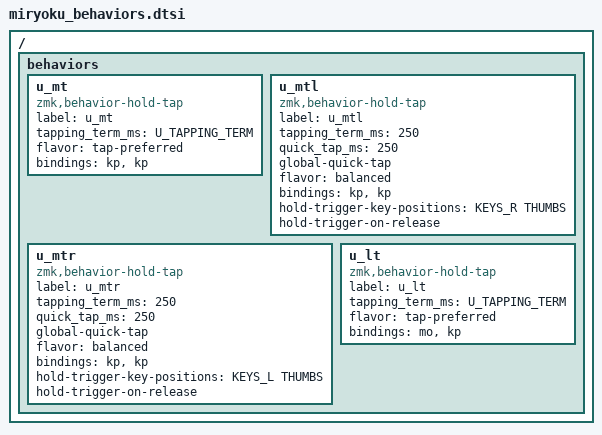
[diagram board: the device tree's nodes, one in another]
// Copyright 2022 Manna Harbour
// https://github.com/manna-harbour/miryoku

#define KEYS_L  0  1  2  3  4 05 12 13 14 15 16 17 24 25 26 27 28 29 36 37 38 39 40 41 42 // left-hand keys
#define KEYS_R  6  7  8  9 10 11 18 19 20 21 22 23 30 31 32 33 34 35 43 44 45 46 47 48 49 // right-hand keys
#define THUMBS 50 51 52 53 54 55 56 57                                                    // thumb keys

/ {
  behaviors {
    u_mt: u_mt {
      compatible = "zmk,behavior-hold-tap";
      label = "u_mt";
      #binding-cells = <2>;
      tapping_term_ms = <U_TAPPING_TERM>;
      flavor = "tap-preferred";
      bindings = <&kp>, <&kp>;
    };
    u_mtl: u_mtl {
      compatible = "zmk,behavior-hold-tap";
      label = "u_mtl";
      #binding-cells = <2>;
      tapping_term_ms = <250>;
      quick_tap_ms = <250>; // Should be > ( 10500 / Relaxed WPM )
      global-quick-tap;
      flavor = "balanced";
      bindings = <&kp>, <&kp>;
      hold-trigger-key-positions = <KEYS_R THUMBS>;
      hold-trigger-on-release;
    };
    u_mtr: u_mtr {
      compatible = "zmk,behavior-hold-tap";
      label = "u_mtr";
      #binding-cells = <2>;
      tapping_term_ms = <250>;
      quick_tap_ms = <250>;
      global-quick-tap;
      flavor = "balanced";
      bindings = <&kp>, <&kp>;
      hold-trigger-key-positions = <KEYS_L THUMBS>;
      hold-trigger-on-release;
    };
    u_lt: u_lt {
      compatible = "zmk,behavior-hold-tap";
      label = "u_lt";
      #binding-cells = <2>;
      tapping_term_ms = <U_TAPPING_TERM>;
      flavor = "tap-preferred";
      bindings = <&mo>, <&kp>;
    };
  };
};
